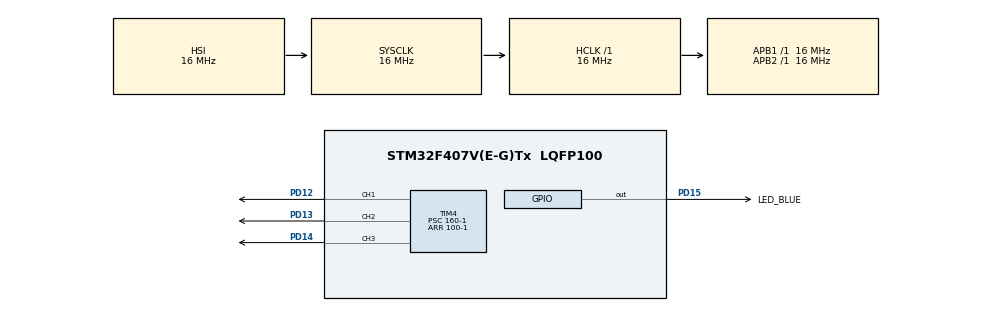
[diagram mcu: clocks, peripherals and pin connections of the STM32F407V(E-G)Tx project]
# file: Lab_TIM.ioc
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Mcu.Family=STM32F4
Mcu.Name=STM32F407V(E-G)Tx
Mcu.Package=LQFP100
NVIC.PriorityGroup=NVIC_PRIORITYGROUP_4
NVIC.TIM6_DAC_IRQn=true\:0\:0\:false\:false\:true\:true\:true\:true
PA13.Mode=Serial_Wire
PA13.Signal=SYS_JTMS-SWDIO
PA14.Mode=Serial_Wire
PA14.Signal=SYS_JTCK-SWCLK
PD12.Signal=S_TIM4_CH1
PD13.Signal=S_TIM4_CH2
PD14.Signal=S_TIM4_CH3
PD15.GPIO_Label=LED_BLUE
PD15.Signal=GPIO_Output
PH0-OSC_IN.Mode=HSE-External-Oscillator
PH0-OSC_IN.Signal=RCC_OSC_IN
PH1-OSC_OUT.Mode=HSE-External-Oscillator
PH1-OSC_OUT.Signal=RCC_OSC_OUT
ProjectManager.HeapSize=0x200
ProjectManager.StackSize=0x400
ProjectManager.TargetToolchain=MDK-ARM V5.32
RCC.AHBFreq_Value=16000000
RCC.APB1Freq_Value=16000000
RCC.APB2Freq_Value=16000000
RCC.CortexFreq_Value=16000000
RCC.HSE_VALUE=25000000
RCC.HSI_VALUE=16000000
RCC.LSE_VALUE=32768
RCC.SYSCLKFreq_VALUE=16000000
RCC.VCOOutputFreq_Value=192000000
SH.S_TIM4_CH1.0=TIM4_CH1,PWM Generation1 CH1
SH.S_TIM4_CH2.0=TIM4_CH2,PWM Generation2 CH2
SH.S_TIM4_CH3.0=TIM4_CH3,PWM Generation3 CH3
TIM4.Channel-PWM\ Generation1\ CH1=TIM_CHANNEL_1
TIM4.Channel-PWM\ Generation2\ CH2=TIM_CHANNEL_2
TIM4.Channel-PWM\ Generation3\ CH3=TIM_CHANNEL_3
TIM4.Period=100-1
TIM4.Prescaler=160-1
TIM4.Pulse-PWM\ Generation1\ CH1=50-1
TIM4.Pulse-PWM\ Generation2\ CH2=25-1
TIM4.Pulse-PWM\ Generation3\ CH3=10-1
TIM6.Period=1000-1
TIM6.Prescaler=16000-1
VP_TIM4_VS_ClockSourceINT.Mode=Internal
VP_TIM6_VS_ClockSourceINT.Mode=Enable_Timer
board=custom

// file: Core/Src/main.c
/* USER CODE BEGIN Header */
/**
  ******************************************************************************
  * @file           : main.c
  * @brief          : Main program body
  ******************************************************************************
  * @attention
  *
  * Copyright (c) 2023 STMicroelectronics.
  * All rights reserved.
  *
  * This software is licensed under terms that can be found in the LICENSE file
  * in the root directory of this software component.
  * If no LICENSE file comes with this software, it is provided AS-IS.
  *
  ******************************************************************************
  */
/* USER CODE END Header */
#include "main.h"
#include "tim.h"
#include "gpio.h"

/* USER CODE BEGIN Includes */
#define POWER_MAX 100
/* USER CODE END Includes */

/* USER CODE BEGIN PV */
uint8_t power = 0;
/* USER CODE END PV */

void SystemClock_Config(void);

int main(void)
{

  /* MCU Configuration--------------------------------------------------------*/

  /* Reset of all peripherals, Initializes the Flash interface and the Systick. */
  HAL_Init();

  /* Configure the system clock */
  SystemClock_Config();

  /* Initialize all configured peripherals */
  MX_GPIO_Init();
  MX_TIM4_Init();
  MX_TIM6_Init();
  /* USER CODE BEGIN 2 */
	HAL_TIM_PWM_Start(&htim4, TIM_CHANNEL_1);
	HAL_TIM_PWM_Start(&htim4, TIM_CHANNEL_2);
	HAL_TIM_PWM_Start(&htim4, TIM_CHANNEL_3);
  /* USER CODE END 2 */

  /* Infinite loop */
  /* USER CODE BEGIN WHILE */
  while (1)
  {
	  __HAL_TIM_SET_COMPARE(&htim4, TIM_CHANNEL_1, power);
	  __HAL_TIM_SET_COMPARE(&htim4, TIM_CHANNEL_2, POWER_MAX - power - 1);
	  HAL_Delay(100);
	  power += 1;
	  if (power >= POWER_MAX)
	  {
		  power = 0;
	  }
    /* USER CODE END WHILE */

  }
}

void SystemClock_Config(void)
{
  RCC_OscInitTypeDef RCC_OscInitStruct = {0};
  RCC_ClkInitTypeDef RCC_ClkInitStruct = {0};

  /** Configure the main internal regulator output voltage
  */
  __HAL_RCC_PWR_CLK_ENABLE();
  __HAL_PWR_VOLTAGESCALING_CONFIG(PWR_REGULATOR_VOLTAGE_SCALE1);

  /** Initializes the RCC Oscillators according to the specified parameters
  * in the RCC_OscInitTypeDef structure.
  */
  RCC_OscInitStruct.OscillatorType = RCC_OSCILLATORTYPE_HSI;
  RCC_OscInitStruct.HSIState = RCC_HSI_ON;
  RCC_OscInitStruct.HSICalibrationValue = RCC_HSICALIBRATION_DEFAULT;
  RCC_OscInitStruct.PLL.PLLState = RCC_PLL_NONE;
  if (HAL_RCC_OscConfig(&RCC_OscInitStruct) != HAL_OK)
  {
    Error_Handler();
  }

  /** Initializes the CPU, AHB and APB buses clocks
  */
  RCC_ClkInitStruct.ClockType = RCC_CLOCKTYPE_HCLK|RCC_CLOCKTYPE_SYSCLK
                              |RCC_CLOCKTYPE_PCLK1|RCC_CLOCKTYPE_PCLK2;
  RCC_ClkInitStruct.SYSCLKSource = RCC_SYSCLKSOURCE_HSI;
  RCC_ClkInitStruct.AHBCLKDivider = RCC_SYSCLK_DIV1;
  RCC_ClkInitStruct.APB1CLKDivider = RCC_HCLK_DIV1;
  RCC_ClkInitStruct.APB2CLKDivider = RCC_HCLK_DIV1;

  if (HAL_RCC_ClockConfig(&RCC_ClkInitStruct, FLASH_LATENCY_0) != HAL_OK)
  {
    Error_Handler();
  }
}

void Error_Handler(void)
{
  __disable_irq();
  while (1)
  {
  }
}
